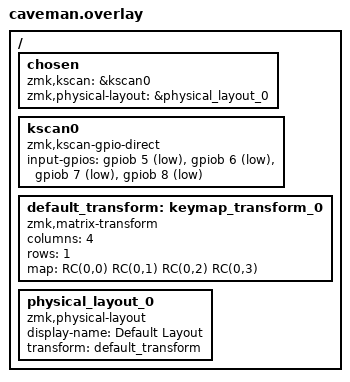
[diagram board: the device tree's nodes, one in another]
#include <dt-bindings/zmk/matrix_transform.h>

/ {
    chosen {
        zmk,kscan = &kscan0;
        zmk,physical-layout = &physical_layout_0;
    };

    kscan0: kscan0 {
        compatible = "zmk,kscan-gpio-direct";
        // wakeup-source;
        input-gpios
            = <&gpiob 5 (GPIO_ACTIVE_LOW | GPIO_PULL_UP)>
            , <&gpiob 6 (GPIO_ACTIVE_LOW | GPIO_PULL_UP)>
            , <&gpiob 7 (GPIO_ACTIVE_LOW | GPIO_PULL_UP)>
            , <&gpiob 8 (GPIO_ACTIVE_LOW | GPIO_PULL_UP)>
            ;
    };

    default_transform: keymap_transform_0 {
        compatible = "zmk,matrix-transform";
        columns = <4>;
        rows = <1>;
        map = <
            RC(0,0) RC(0,1) RC(0,2) RC(0,3)
        >;
    };

    physical_layout_0: physical_layout_0 {
        compatible = "zmk,physical-layout";
        display-name = "Default Layout";
        transform = <&default_transform>;
    };
};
